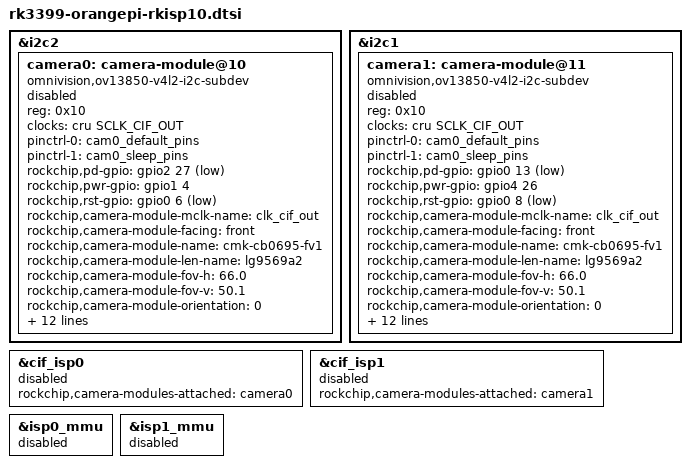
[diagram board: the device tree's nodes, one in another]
/*
* This program is free software; you can redistribute it and/or
* modify it under the terms of the GNU General Public License
* as published by the Free Software Foundation; either version 2
* of the License, or (at your option) any later version.
*
* This program is distributed in the hope that it will be useful,
* but WITHOUT ANY WARRANTY; without even the implied warranty of
* MERCHANTABILITY or FITNESS FOR A PARTICULAR PURPOSE. See the
* GNU General Public License for more details.
*
* You should have received a copy of the GNU General Public License
* along with this program; if not, you can access it online at
* http://www.gnu.org/licenses/gpl-2.0.html.
*/

&i2c2 {
        status = "okay";
        camera0: camera-module@10 {
                status = "disable";
                compatible = "omnivision,ov13850-v4l2-i2c-subdev";
                reg = < 0x10 >;
                device_type = "v4l2-i2c-subdev";
                clocks = <&cru SCLK_CIF_OUT>;
                clock-names = "clk_cif_out";
                pinctrl-names = "rockchip,camera_default","rockchip,camera_sleep";
                pinctrl-0 = <&cam0_default_pins>;
                pinctrl-1 = <&cam0_sleep_pins>;
                rockchip,pd-gpio = <&gpio2 27 GPIO_ACTIVE_LOW>;
                rockchip,pwr-gpio = <&gpio1 4 GPIO_ACTIVE_HIGH>;
                rockchip,rst-gpio = <&gpio0 6 GPIO_ACTIVE_LOW>;
                rockchip,camera-module-mclk-name = "clk_cif_out";
                rockchip,camera-module-facing = "front";
                rockchip,camera-module-name = "cmk-cb0695-fv1";
                rockchip,camera-module-len-name = "lg9569a2";
                rockchip,camera-module-fov-h = "66.0";
                rockchip,camera-module-fov-v = "50.1";
                rockchip,camera-module-orientation = <0>;
                rockchip,camera-module-iq-flip = <0>;
                rockchip,camera-module-iq-mirror = <0>;
                rockchip,camera-module-flip = <1>;
                rockchip,camera-module-mirror = <0>;

                rockchip,camera-module-defrect0 = <2112 1568 0 0 2112 1568>;
                rockchip,camera-module-defrect1 = <4224 3136 0 0 4224 3136>;
                rockchip,camera-module-defrect3 = <3264 2448 0 0 3264 2448>;
                rockchip,camera-module-flash-support = <0>;
                rockchip,camera-module-mipi-dphy-index = <0>;
        };

};

&i2c1 {
        camera1: camera-module@11 {
                status = "disable";
                compatible = "omnivision,ov13850-v4l2-i2c-subdev";
                reg = < 0x10 >;
                device_type = "v4l2-i2c-subdev";
                clocks = <&cru SCLK_CIF_OUT>;
                clock-names = "clk_cif_out";
                pinctrl-names = "rockchip,camera_default","rockchip,camera_sleep";
                pinctrl-0 = <&cam0_default_pins>;
                pinctrl-1 = <&cam0_sleep_pins>;
                rockchip,pd-gpio = <&gpio0 13 GPIO_ACTIVE_LOW>;
                rockchip,pwr-gpio = <&gpio4 26 GPIO_ACTIVE_HIGH>;
                rockchip,rst-gpio = <&gpio0 8 GPIO_ACTIVE_LOW>;
                rockchip,camera-module-mclk-name = "clk_cif_out";
                rockchip,camera-module-facing = "front";
                rockchip,camera-module-name = "cmk-cb0695-fv1";
                rockchip,camera-module-len-name = "lg9569a2";
                rockchip,camera-module-fov-h = "66.0";
                rockchip,camera-module-fov-v = "50.1";
                rockchip,camera-module-orientation = <0>; 
                rockchip,camera-module-iq-flip = <0>; 
                rockchip,camera-module-iq-mirror = <0>; 
                rockchip,camera-module-flip = <1>; 
                rockchip,camera-module-mirror = <0>; 

                rockchip,camera-module-defrect0 = <2112 1568 0 0 2112 1568>;
                rockchip,camera-module-defrect1 = <4224 3136 0 0 4224 3136>;
                rockchip,camera-module-defrect3 = <3264 2448 0 0 3264 2448>;
                rockchip,camera-module-flash-support = <0>; 
                rockchip,camera-module-mipi-dphy-index = <1>; 
        };   

};


&cif_isp0 {
 rockchip,camera-modules-attached = <&camera0>;
 status = "disable";
};

&cif_isp1 {
        rockchip,camera-modules-attached = <&camera1>;
        status = "disable";
};

&isp0_mmu {
        status = "disable";
};
&isp1_mmu {
        status = "disable";
};
